AUTOSAR XML (schema 00046)
package /MICROSAR/Csm_swc/DataTypes
  22 x impl type:
    Csm_VerifyResultType: compu {0=CRYPTO_E_VER_OK, 1=CRYPTO_E_VER_NOT_OK}, range raw 0..1, implementation-data-type=uint8  # The data type Csm_VerifyResultType indicates the result of a verification operation.
    Csm_ConfigIdType: range raw 0..65535, implementation-data-type=uint16  # The data type Csm_ConfigIdType identifies a configuration data set, which is unique within a service.
    Crypto_OperationModeType: compu {1=CRYPTO_OPERATIONMODE_START, 2=CRYPTO_OPERATIONMODE_UPDATE, 3=CRYPTO_OPERATIONMODE_STREAMSTART, 4=CRYPTO_OPERATIONMODE_FINISH, 7=CRYPTO_OPERATIONMODE_SINGLECALL}, range raw 0..7, implementation-data-type=uint8  # Enum which operation shall be performed. This enum is constructed from a bit mask, where the first bit indicates “Start”, the second “Update” and the third “Finish”.
    Crypto_VerifyResultType: compu {0=CRYPTO_E_VER_OK, 1=CRYPTO_E_VER_NOT_OK}, range raw 0..1, implementation-data-type=uint8  # Enumeration of the result type of verification operations.
    Csm_KeyElementEnumType:  # Enum which lists the most common Crypto Key Elements IDs
      compu {1=CRYPTO_KE_MAC_KEY, 2=CRYPTO_KE_MAC_PROOF, 1=CRYPTO_KE_SIGNATURE_KEY, 3=CRYPTO_KE_RANDOM_SEED_STATE, 4=CRYPTO_KE_RANDOM_ALGORITHM, 1=CRYPTO_KE_CIPHER_KEY, 5=CRYPTO_KE_CIPHER_IV, 6=CRYPTO_KE_CIPHER_PROOF, 7=CRYPTO_KE_CIPHER_2NDKEY, 8=CRYPTO_KE_KEYEXCHANGE_BASE, 9=CRYPTO_KE_KEYEXCHANGE_PRIVKEY, 10=CRYPTO_KE_KEYEXCHANGE_OWNPUBKEY, 1=CRYPTO_KE_KEYEXCHANGE_SHAREDVALUE, 12=CRYPTO_KE_KEYEXCHANGE_ALGORITHM, 1=CRYPTO_KE_KEYDERIVATION_PASSWORD, 13=CRYPTO_KE_KEYDERIVATION_SALT, 14=CRYPTO_KE_KEYDERIVATION_ITERATIONS, 15=CRYPTO_KE_KEYDERIVATION_ALGORITHM, 1=CRYPTO_KE_KEYGENERATE_KEY, 16=CRYPTO_KE_KEYGENERATE_SEED, 17=CRYPTO_KE_KEYGENERATE_ALGORITHM, 0=CRYPTO_KE_CERTIFICATE_DATA, 18=CRYPTO_KE_CERTIFICATE_PARSING_FORMAT, 19=CRYPTO_KE_CERTIFICATE_CURRENT_TIME, 20=CRYPTO_KE_CERTIFICATE_VERSION, 21=CRYPTO_KE_CERTIFICATE_SERIALNUMBER, 22=CRYPTO_KE_CERTIFICATE_SIGNATURE_ALGORITHM, 23=CRYPTO_KE_CERTIFICATE_ISSUER, 24=CRYPTO_KE_CERTIFICATE_VALIDITY_NOT_BEFORE, 25=CRYPTO_KE_CERTIFICATE_VALIDITY_NOT_AFTER, 26=CRYPTO_KE_CERTIFICATE_SUBJECT, 1=CRYPTO_KE_CERTIFICATE_SUBJECT_PUBLIC_KEY, 27=CRYPTO_KE_CERTIFICATE_EXTENSIONS, 28=CRYPTO_KE_CERTIFICATE_SIGNATURE}
      range raw 0..4294967295
      implementation-data-type=uint32
    Csm_DataPtr: category=DATA_REFERENCE, sw-pointer-target-props={target-category=TYPE_REFERENCE, implementation-data-type=uint8}
    Csm_const_DataPtr: category=DATA_REFERENCE, sw-pointer-target-props={target-category=TYPE_REFERENCE, implementation-data-type=uint8, sw-impl-policy=CONST}
    Csm_LengthPtr: category=DATA_REFERENCE, sw-pointer-target-props={target-category=TYPE_REFERENCE, implementation-data-type=uint32}
    Csm_VerifyResultPtr: category=DATA_REFERENCE, sw-pointer-target-props={target-category=TYPE_REFERENCE, implementation-data-type=Csm_VerifyResultType}
    Csm_ResultType: compu {1=E_NOT_OK, 2=E_SMALL_BUFFER, 3=E_ENTROPY_EXHAUSTION, 4=E_KEY_READ_FAIL, 5=E_KEY_NOT_AVAILABLE, 6=E_KEY_NOT_VALID, 7=E_JOB_CANCELED, 8=E_KEY_EMPTY}, range raw 0..8, implementation-data-type=uint8  # Csm module specific return values for use in Std_ReturnType that could occur during asynchronous job processing.
    Crypto_ResultType: compu {1=E_NOT_OK, 2=CRYPTO_E_BUSY, 4=CRYPTO_E_ENTROPY_EXHAUSTED, 6=CRYPTO_E_KEY_READ_FAIL, 7=CRYPTO_E_KEY_WRITE_FAIL, 8=CRYPTO_E_KEY_NOT_AVAILABLE, 9=CRYPTO_E_KEY_NOT_VALID, 10=CRYPTO_E_KEY_SIZE_MISMATCH, 12=CRYPTO_E_JOB_CANCELED, 13=CRYPTO_E_KEY_EMPTY}, range raw 0..13, implementation-data-type=uint8  # Return for Std_ReturnType for Cryptostack.
    dtRef_: implementation-data-type=uint8
    Csm_DecryptDataType_CsmPrimitives_AES128_Decrypt: category=ARRAY, sw-calibration-access=READ-ONLY  # Used as Buffer for service.
      element Csm_DecryptDataType_CsmPrimitives_AES128_DecryptElement: array-size=16, array-size-semantics=FIXED-SIZE, implementation-data-type=uint8
    Csm_DecryptResultType_CsmPrimitives_AES128_Decrypt: category=ARRAY, sw-calibration-access=READ-ONLY  # Used as Buffer for service.
      element Csm_DecryptResultType_CsmPrimitives_AES128_DecryptElement: array-size=16, array-size-semantics=FIXED-SIZE, implementation-data-type=uint8
    Csm_EncryptDataType_CsmPrimitives_AES128_Encrypt: category=ARRAY, sw-calibration-access=READ-ONLY  # Used as Buffer for service.
      element Csm_EncryptDataType_CsmPrimitives_AES128_EncryptElement: array-size=16, array-size-semantics=FIXED-SIZE, implementation-data-type=uint8
    Csm_EncryptResultType_CsmPrimitives_AES128_Encrypt: category=ARRAY, sw-calibration-access=READ-ONLY  # Used as Buffer for service.
      element Csm_EncryptResultType_CsmPrimitives_AES128_EncryptElement: array-size=16, array-size-semantics=FIXED-SIZE, implementation-data-type=uint8
    Csm_KeyDataType_CsmKey: category=ARRAY, sw-calibration-access=READ-ONLY  # Used as Buffer for service.
      element Csm_KeyDataType_CsmKeyElement: array-size=16, array-size-semantics=FIXED-SIZE, implementation-data-type=uint8
    Csm_PublicValueDataType_CsmKey: category=ARRAY, sw-calibration-access=READ-ONLY  # Used as Buffer for service.
      element Csm_PublicValueDataType_CsmKeyElement: array-size=16, array-size-semantics=FIXED-SIZE, implementation-data-type=uint8
    Csm_SeedDataTypeCsmKey: category=ARRAY, sw-calibration-access=READ-ONLY  # Used as Buffer for service.
      element Csm_SeedDataTypeCsmKeyElement: array-size=16, array-size-semantics=FIXED-SIZE, implementation-data-type=uint8
    Csm_KeyDataType_CsmKey_RandomSeed: category=ARRAY, sw-calibration-access=READ-ONLY  # Used as Buffer for service.
      element Csm_KeyDataType_CsmKey_RandomSeedElement: array-size=16, array-size-semantics=FIXED-SIZE, implementation-data-type=uint8
    Csm_PublicValueDataType_CsmKey_RandomSeed: category=ARRAY, sw-calibration-access=READ-ONLY  # Used as Buffer for service.
      element Csm_PublicValueDataType_CsmKey_RandomSeedElement: array-size=16, array-size-semantics=FIXED-SIZE, implementation-data-type=uint8
    Csm_SeedDataTypeCsmKey_RandomSeed: category=ARRAY, sw-calibration-access=READ-ONLY  # Used as Buffer for service.
      element Csm_SeedDataTypeCsmKey_RandomSeedElement: array-size=16, array-size-semantics=FIXED-SIZE, implementation-data-type=uint8
package /MICROSAR/Csm_swc/Interfaces
  5 x client server interface, all with is-service=true, service-kind=CRYPTO-SERVICE-MANAGER:
    CsmKeyManagement_CsmKey  # Interface to execute the key management functions.
      13 x operation:
        CertificateParse: possible-error=[CsmKeyManagement_CsmKey/E_NOT_OK, CsmKeyManagement_CsmKey/CSM_E_BUSY, CsmKeyManagement_CsmKey/CSM_E_KEY_EMPTY]  # This function shall dispatch the certificate parse function to the CRYIF.
        CertificateVerify: possible-error=[CsmKeyManagement_CsmKey/E_NOT_OK, CsmKeyManagement_CsmKey/CSM_E_BUSY, CsmKeyManagement_CsmKey/CSM_E_KEY_EMPTY]  # Verifies the certificate stored in the key referenced by verifyKeyId with the certificate stored in the key referenced by keyId. Note: Only certificates stored in the same Crypto Driver can be verified against each other. If the key element CRYPTO_KE_CERTIFICATE_CURRENT_TIME is used for the verification of the validity period of the certificate indentified by verifyKeyId, it shall have the same format as the timestamp in the certificate.
          arg verifyKeyId: type=uint32, direction=IN  # Holds the identifier of the key containing the certificate to be verified.
          arg verifyPtr: type=Crypto_VerifyResultType, direction=OUT  # Contains the result of the certificate verification.
        KeyCopy: possible-error=[CsmKeyManagement_CsmKey/E_NOT_OK, CsmKeyManagement_CsmKey/CSM_E_BUSY, CsmKeyManagement_CsmKey/CSM_E_SMALL_BUFFER, CsmKeyManagement_CsmKey/CSM_E_KEY_READ_FAIL, CsmKeyManagement_CsmKey/CSM_E_KEY_WRITE_FAIL, CsmKeyManagement_CsmKey/CSM_E_KEY_SIZE_MISMATCH, CsmKeyManagement_CsmKey/CSM_E_KEY_EMPTY]  # This function shall copy all key elements from the source key to a target key.
          arg targetKeyId: type=uint32, direction=IN  # Holds the identifier of the key whose key element shall be the destination element.
        KeyDerive: possible-error=[CsmKeyManagement_CsmKey/E_NOT_OK, CsmKeyManagement_CsmKey/CSM_E_BUSY, CsmKeyManagement_CsmKey/CSM_E_KEY_READ_FAIL, CsmKeyManagement_CsmKey/CSM_E_KEY_WRITE_FAIL, CsmKeyManagement_CsmKey/CSM_E_KEY_SIZE_MISMATCH, CsmKeyManagement_CsmKey/CSM_E_KEY_EMPTY]  # Derives a new key by using the key elements in the given key. The given key contains the key elements for the password and salt. The derived key is stored in the key element with the id 1 of the key identified by targetCryptoKeyId.
          arg targetKeyId: type=uint32, direction=IN  # Holds the identifier of the key which is used to store the derived key.
        KeyElementCopy: possible-error=[CsmKeyManagement_CsmKey/E_NOT_OK, CsmKeyManagement_CsmKey/CSM_E_BUSY, CsmKeyManagement_CsmKey/CSM_E_SMALL_BUFFER, CsmKeyManagement_CsmKey/CSM_E_KEY_READ_FAIL, CsmKeyManagement_CsmKey/CSM_E_KEY_WRITE_FAIL, CsmKeyManagement_CsmKey/CSM_E_KEY_SIZE_MISMATCH, CsmKeyManagement_CsmKey/CSM_E_KEY_EMPTY]  # This function shall copy a key elements from one key to a target key.
          arg keyElementId: type=uint32, direction=IN  # Holds the identifier of the key element which shall be the source for the copy operation.
          arg targetKeyId: type=uint32, direction=IN  # Holds the identifier of the key whose key element shall be the destination element.
          arg targetKeyElementId: type=uint32, direction=IN  # Holds the identifier of the key element which shall be the destination for the copy operation.
        KeyElementCopyPartial: possible-error=[CsmKeyManagement_CsmKey/E_NOT_OK, CsmKeyManagement_CsmKey/CSM_E_BUSY, CsmKeyManagement_CsmKey/CSM_E_KEY_NOT_AVAILABLE, CsmKeyManagement_CsmKey/CSM_E_KEY_READ_FAIL, CsmKeyManagement_CsmKey/CSM_E_KEY_WRITE_FAIL, CsmKeyManagement_CsmKey/CSM_E_KEY_SIZE_MISMATCH, CsmKeyManagement_CsmKey/CSM_E_KEY_EMPTY]  # This function shall copy parts of a key element from one key to parts of a target key element of a target key.
          6 x arg, all with type=uint32, direction=IN:
            keyElementId  # Holds the identifier of the key element which shall be the source for the copy operation.
            keyElementSourceOffset  # This is the offset of the source key element indicating the start index of the copy operation.
            keyElementTargetOffset  # This is the offset of the destination key element indicating the start index of the copy operation.
            keyElementCopyLength  # Specifies the number of bytes that shall be copied.
            targetKeyId  # Holds the identifier of the key whose key element shall be the destination element.
            targetKeyElementId  # Holds the identifier of the key element which shall be the destination for the copy operation.
        KeyElementGet: possible-error=[CsmKeyManagement_CsmKey/E_NOT_OK, CsmKeyManagement_CsmKey/CSM_E_BUSY, CsmKeyManagement_CsmKey/CSM_E_SMALL_BUFFER, CsmKeyManagement_CsmKey/CSM_E_KEY_READ_FAIL, CsmKeyManagement_CsmKey/CSM_E_KEY_NOT_AVAILABLE, CsmKeyManagement_CsmKey/CSM_E_KEY_EMPTY]  # Retrieves the key element bytes from a specific key element of the key and stores the key element in the provided buffer.
          arg keyElementId: type=uint32, direction=IN  # Holds the identifier of the key element to be read.
          arg keyPtr: type=Csm_KeyDataType_CsmKey, direction=OUT, server-argument-impl-policy=USE-ARRAY-BASE-TYPE  # Holds the data to the key element bytes to be written.
          arg keyLength: type=uint32, direction=INOUT  # Contains the number of key element bytes.
        KeyElementSet: possible-error=[CsmKeyManagement_CsmKey/E_NOT_OK, CsmKeyManagement_CsmKey/CSM_E_BUSY, CsmKeyManagement_CsmKey/CSM_E_KEY_WRITE_FAIL, CsmKeyManagement_CsmKey/CSM_E_KEY_NOT_AVAILABLE, CsmKeyManagement_CsmKey/CSM_E_KEY_SIZE_MISMATCH]  # Sets the given key element bytes to the key.
          arg keyElementId: type=uint32, direction=IN  # Holds the identifier of the key element to be written.
          arg keyPtr: type=Csm_KeyDataType_CsmKey, direction=IN, server-argument-impl-policy=USE-ARRAY-BASE-TYPE  # Holds the data to the key element bytes to be processed.
          arg keyLength: type=uint32, direction=IN  # Contains the number of key element bytes.
        KeyExchangeCalcPubVal: possible-error=[CsmKeyManagement_CsmKey/E_NOT_OK, CsmKeyManagement_CsmKey/CSM_E_BUSY, CsmKeyManagement_CsmKey/CSM_E_SMALL_BUFFER, CsmKeyManagement_CsmKey/CSM_E_KEY_EMPTY]  # Calculates the public value of the current user for the key exchange and stores the public key in the provided buffer.
          arg publicValuePtr: type=Csm_PublicValueDataType_CsmKey, direction=OUT, server-argument-impl-policy=USE-ARRAY-BASE-TYPE  # Holds a pointer to the memory location in which the public value length in bytes is stored. On calling this function, this parameter shall contain the size of the buffer in bytes provided by publicValuePtr. When the request has finished, the actual length of the returned value shall be stored.
          arg publicValueLengthPtr: type=uint32, direction=INOUT  # Contains the pointer to the data where the public value shall be stored.
        KeyExchangeCalcSecret: possible-error=[CsmKeyManagement_CsmKey/E_NOT_OK, CsmKeyManagement_CsmKey/CSM_E_BUSY, CsmKeyManagement_CsmKey/CSM_E_SMALL_BUFFER, CsmKeyManagement_CsmKey/CSM_E_KEY_EMPTY]  # Calculates the shared secret key for the key exchange with the key material of the key identified by the keyId and the partner public key. The shared secret key is stored as a key element in the same key.
          arg partnerPublicValuePtr: type=Csm_PublicValueDataType_CsmKey, direction=IN, server-argument-impl-policy=USE-ARRAY-BASE-TYPE  # Holds the pointer to the memory location containing the partner's public value.
          arg partnerPublicValueLength: type=uint32, direction=IN  # Contains the number of bytes of the partner public value.
        KeyGenerate: possible-error=[CsmKeyManagement_CsmKey/E_NOT_OK, CsmKeyManagement_CsmKey/CSM_E_BUSY, CsmKeyManagement_CsmKey/CSM_E_KEY_EMPTY]  # Generates new key material and store it in the key identified by keyId.
        KeySetValid: possible-error=[CsmKeyManagement_CsmKey/E_NOT_OK, CsmKeyManagement_CsmKey/CSM_E_BUSY]  # Sets the given key element bytes to the key.
        RandomSeed: possible-error=[CsmKeyManagement_CsmKey/E_NOT_OK, CsmKeyManagement_CsmKey/CSM_E_BUSY]  # Feeds a key element with a random seed.
          arg seedPtr: type=Csm_SeedDataTypeCsmKey, direction=IN, server-argument-impl-policy=USE-ARRAY-BASE-TYPE  # Holds the data which shall be used for the random seed initialization.
          arg seedLength: type=uint32, direction=IN  # Contains the length of the seed in bytes.
      8 x error:
        E_NOT_OK: error-code=1  # The service request failed.
        CSM_E_BUSY: error-code=2  # The service request failed because the service is still busy.
        CSM_E_SMALL_BUFFER: error-code=3  # The service request failed because the provided buffer is too small to store the result.
        CSM_E_KEY_READ_FAIL: error-code=6  # The service request failed because read access was denied.
        CSM_E_KEY_WRITE_FAIL: error-code=7  # The service request failed because write access was denied.
        CSM_E_KEY_NOT_AVAILABLE: error-code=8  # The service request failed because the key is not available.
        CSM_E_KEY_SIZE_MISMATCH: error-code=10  # The service request failed because the key element is not partially accessible and the provided key element length is too short or too long for that key element.
        CSM_E_KEY_EMPTY: error-code=13  # The service request failed because of uninitialized source key element.
    CsmKeyManagement_CsmKey_RandomSeed  # Interface to execute the key management functions.
      13 x operation:
        CertificateParse: possible-error=[CsmKeyManagement_CsmKey_RandomSeed/E_NOT_OK, CsmKeyManagement_CsmKey_RandomSeed/CSM_E_BUSY, CsmKeyManagement_CsmKey_RandomSeed/CSM_E_KEY_EMPTY]  # This function shall dispatch the certificate parse function to the CRYIF.
        CertificateVerify: possible-error=[CsmKeyManagement_CsmKey_RandomSeed/E_NOT_OK, CsmKeyManagement_CsmKey_RandomSeed/CSM_E_BUSY, CsmKeyManagement_CsmKey_RandomSeed/CSM_E_KEY_EMPTY]  # Verifies the certificate stored in the key referenced by verifyKeyId with the certificate stored in the key referenced by keyId. Note: Only certificates stored in the same Crypto Driver can be verified against each other. If the key element CRYPTO_KE_CERTIFICATE_CURRENT_TIME is used for the verification of the validity period of the certificate indentified by verifyKeyId, it shall have the same format as the timestamp in the certificate.
          arg verifyKeyId: type=uint32, direction=IN  # Holds the identifier of the key containing the certificate to be verified.
          arg verifyPtr: type=Crypto_VerifyResultType, direction=OUT  # Contains the result of the certificate verification.
        KeyCopy: possible-error=[CsmKeyManagement_CsmKey_RandomSeed/E_NOT_OK, CsmKeyManagement_CsmKey_RandomSeed/CSM_E_BUSY, CsmKeyManagement_CsmKey_RandomSeed/CSM_E_SMALL_BUFFER, CsmKeyManagement_CsmKey_RandomSeed/CSM_E_KEY_READ_FAIL, CsmKeyManagement_CsmKey_RandomSeed/CSM_E_KEY_WRITE_FAIL, CsmKeyManagement_CsmKey_RandomSeed/CSM_E_KEY_SIZE_MISMATCH, CsmKeyManagement_CsmKey_RandomSeed/CSM_E_KEY_EMPTY]  # This function shall copy all key elements from the source key to a target key.
          arg targetKeyId: type=uint32, direction=IN  # Holds the identifier of the key whose key element shall be the destination element.
        KeyDerive: possible-error=[CsmKeyManagement_CsmKey_RandomSeed/E_NOT_OK, CsmKeyManagement_CsmKey_RandomSeed/CSM_E_BUSY, CsmKeyManagement_CsmKey_RandomSeed/CSM_E_KEY_READ_FAIL, CsmKeyManagement_CsmKey_RandomSeed/CSM_E_KEY_WRITE_FAIL, CsmKeyManagement_CsmKey_RandomSeed/CSM_E_KEY_SIZE_MISMATCH, CsmKeyManagement_CsmKey_RandomSeed/CSM_E_KEY_EMPTY]  # Derives a new key by using the key elements in the given key. The given key contains the key elements for the password and salt. The derived key is stored in the key element with the id 1 of the key identified by targetCryptoKeyId.
          arg targetKeyId: type=uint32, direction=IN  # Holds the identifier of the key which is used to store the derived key.
        KeyElementCopy: possible-error=[CsmKeyManagement_CsmKey_RandomSeed/E_NOT_OK, CsmKeyManagement_CsmKey_RandomSeed/CSM_E_BUSY, CsmKeyManagement_CsmKey_RandomSeed/CSM_E_SMALL_BUFFER, CsmKeyManagement_CsmKey_RandomSeed/CSM_E_KEY_READ_FAIL, CsmKeyManagement_CsmKey_RandomSeed/CSM_E_KEY_WRITE_FAIL, CsmKeyManagement_CsmKey_RandomSeed/CSM_E_KEY_SIZE_MISMATCH, CsmKeyManagement_CsmKey_RandomSeed/CSM_E_KEY_EMPTY]  # This function shall copy a key elements from one key to a target key.
          arg keyElementId: type=uint32, direction=IN  # Holds the identifier of the key element which shall be the source for the copy operation.
          arg targetKeyId: type=uint32, direction=IN  # Holds the identifier of the key whose key element shall be the destination element.
          arg targetKeyElementId: type=uint32, direction=IN  # Holds the identifier of the key element which shall be the destination for the copy operation.
        KeyElementCopyPartial: possible-error=[CsmKeyManagement_CsmKey_RandomSeed/E_NOT_OK, CsmKeyManagement_CsmKey_RandomSeed/CSM_E_BUSY, CsmKeyManagement_CsmKey_RandomSeed/CSM_E_KEY_NOT_AVAILABLE, CsmKeyManagement_CsmKey_RandomSeed/CSM_E_KEY_READ_FAIL, CsmKeyManagement_CsmKey_RandomSeed/CSM_E_KEY_WRITE_FAIL, CsmKeyManagement_CsmKey_RandomSeed/CSM_E_KEY_SIZE_MISMATCH, CsmKeyManagement_CsmKey_RandomSeed/CSM_E_KEY_EMPTY]  # This function shall copy parts of a key element from one key to parts of a target key element of a target key.
          6 x arg, all with type=uint32, direction=IN:
            keyElementId  # Holds the identifier of the key element which shall be the source for the copy operation.
            keyElementSourceOffset  # This is the offset of the source key element indicating the start index of the copy operation.
            keyElementTargetOffset  # This is the offset of the destination key element indicating the start index of the copy operation.
            keyElementCopyLength  # Specifies the number of bytes that shall be copied.
            targetKeyId  # Holds the identifier of the key whose key element shall be the destination element.
            targetKeyElementId  # Holds the identifier of the key element which shall be the destination for the copy operation.
        KeyElementGet: possible-error=[CsmKeyManagement_CsmKey_RandomSeed/E_NOT_OK, CsmKeyManagement_CsmKey_RandomSeed/CSM_E_BUSY, CsmKeyManagement_CsmKey_RandomSeed/CSM_E_SMALL_BUFFER, CsmKeyManagement_CsmKey_RandomSeed/CSM_E_KEY_READ_FAIL, CsmKeyManagement_CsmKey_RandomSeed/CSM_E_KEY_NOT_AVAILABLE, CsmKeyManagement_CsmKey_RandomSeed/CSM_E_KEY_EMPTY]  # Retrieves the key element bytes from a specific key element of the key and stores the key element in the provided buffer.
          arg keyElementId: type=uint32, direction=IN  # Holds the identifier of the key element to be read.
          arg keyPtr: type=Csm_KeyDataType_CsmKey_RandomSeed, direction=OUT, server-argument-impl-policy=USE-ARRAY-BASE-TYPE  # Holds the data to the key element bytes to be written.
          arg keyLength: type=uint32, direction=INOUT  # Contains the number of key element bytes.
        KeyElementSet: possible-error=[CsmKeyManagement_CsmKey_RandomSeed/E_NOT_OK, CsmKeyManagement_CsmKey_RandomSeed/CSM_E_BUSY, CsmKeyManagement_CsmKey_RandomSeed/CSM_E_KEY_WRITE_FAIL, CsmKeyManagement_CsmKey_RandomSeed/CSM_E_KEY_NOT_AVAILABLE, CsmKeyManagement_CsmKey_RandomSeed/CSM_E_KEY_SIZE_MISMATCH]  # Sets the given key element bytes to the key.
          arg keyElementId: type=uint32, direction=IN  # Holds the identifier of the key element to be written.
          arg keyPtr: type=Csm_KeyDataType_CsmKey_RandomSeed, direction=IN, server-argument-impl-policy=USE-ARRAY-BASE-TYPE  # Holds the data to the key element bytes to be processed.
          arg keyLength: type=uint32, direction=IN  # Contains the number of key element bytes.
        KeyExchangeCalcPubVal: possible-error=[CsmKeyManagement_CsmKey_RandomSeed/E_NOT_OK, CsmKeyManagement_CsmKey_RandomSeed/CSM_E_BUSY, CsmKeyManagement_CsmKey_RandomSeed/CSM_E_SMALL_BUFFER, CsmKeyManagement_CsmKey_RandomSeed/CSM_E_KEY_EMPTY]  # Calculates the public value of the current user for the key exchange and stores the public key in the provided buffer.
          arg publicValuePtr: type=Csm_PublicValueDataType_CsmKey_RandomSeed, direction=OUT, server-argument-impl-policy=USE-ARRAY-BASE-TYPE  # Holds a pointer to the memory location in which the public value length in bytes is stored. On calling this function, this parameter shall contain the size of the buffer in bytes provided by publicValuePtr. When the request has finished, the actual length of the returned value shall be stored.
          arg publicValueLengthPtr: type=uint32, direction=INOUT  # Contains the pointer to the data where the public value shall be stored.
        KeyExchangeCalcSecret: possible-error=[CsmKeyManagement_CsmKey_RandomSeed/E_NOT_OK, CsmKeyManagement_CsmKey_RandomSeed/CSM_E_BUSY, CsmKeyManagement_CsmKey_RandomSeed/CSM_E_SMALL_BUFFER, CsmKeyManagement_CsmKey_RandomSeed/CSM_E_KEY_EMPTY]  # Calculates the shared secret key for the key exchange with the key material of the key identified by the keyId and the partner public key. The shared secret key is stored as a key element in the same key.
          arg partnerPublicValuePtr: type=Csm_PublicValueDataType_CsmKey_RandomSeed, direction=IN, server-argument-impl-policy=USE-ARRAY-BASE-TYPE  # Holds the pointer to the memory location containing the partner's public value.
          arg partnerPublicValueLength: type=uint32, direction=IN  # Contains the number of bytes of the partner public value.
        KeyGenerate: possible-error=[CsmKeyManagement_CsmKey_RandomSeed/E_NOT_OK, CsmKeyManagement_CsmKey_RandomSeed/CSM_E_BUSY, CsmKeyManagement_CsmKey_RandomSeed/CSM_E_KEY_EMPTY]  # Generates new key material and store it in the key identified by keyId.
        KeySetValid: possible-error=[CsmKeyManagement_CsmKey_RandomSeed/E_NOT_OK, CsmKeyManagement_CsmKey_RandomSeed/CSM_E_BUSY]  # Sets the given key element bytes to the key.
        RandomSeed: possible-error=[CsmKeyManagement_CsmKey_RandomSeed/E_NOT_OK, CsmKeyManagement_CsmKey_RandomSeed/CSM_E_BUSY]  # Feeds a key element with a random seed.
          arg seedPtr: type=Csm_SeedDataTypeCsmKey_RandomSeed, direction=IN, server-argument-impl-policy=USE-ARRAY-BASE-TYPE  # Holds the data which shall be used for the random seed initialization.
          arg seedLength: type=uint32, direction=IN  # Contains the length of the seed in bytes.
      8 x error:
        E_NOT_OK: error-code=1  # The service request failed.
        CSM_E_BUSY: error-code=2  # The service request failed because the service is still busy.
        CSM_E_SMALL_BUFFER: error-code=3  # The service request failed because the provided buffer is too small to store the result.
        CSM_E_KEY_READ_FAIL: error-code=6  # The service request failed because read access was denied.
        CSM_E_KEY_WRITE_FAIL: error-code=7  # The service request failed because write access was denied.
        CSM_E_KEY_NOT_AVAILABLE: error-code=8  # The service request failed because the key is not available.
        CSM_E_KEY_SIZE_MISMATCH: error-code=10  # The service request failed because the key element is not partially accessible and the provided key element length is too short or too long for that key element.
        CSM_E_KEY_EMPTY: error-code=13  # The service request failed because of uninitialized source key element.
    CsmDecrypt_CsmPrimitives_AES128_Decrypt  # This interface is used to perform the decryption.
      operation Decrypt: possible-error=[CsmDecrypt_CsmPrimitives_AES128_Decrypt/E_NOT_OK, CsmDecrypt_CsmPrimitives_AES128_Decrypt/CSM_E_BUSY, CsmDecrypt_CsmPrimitives_AES128_Decrypt/CSM_E_SMALL_BUFFER, CsmDecrypt_CsmPrimitives_AES128_Decrypt/CSM_E_KEY_NOT_VALID, CsmDecrypt_CsmPrimitives_AES128_Decrypt/CSM_E_KEY_SIZE_MISMATCH, CsmDecrypt_CsmPrimitives_AES128_Decrypt/CSM_E_KEY_EMPTY]  # This interface shall be used to start the Decrypt service of the CSM module.
        4 x arg:
          dataBuffer: type=Csm_DecryptDataType_CsmPrimitives_AES128_Decrypt, direction=IN, server-argument-impl-policy=USE-ARRAY-BASE-TYPE  # Holds a pointer to the data for which a plaintext shall be computed.
          dataLength: type=uint32, direction=IN  # Contains the number of bytes for which the plaintext shall be computed.
          resultBuffer: type=Csm_DecryptResultType_CsmPrimitives_AES128_Decrypt, direction=OUT, server-argument-impl-policy=USE-ARRAY-BASE-TYPE  # Holds a pointer to the memory location which will hold the plaintext. The memory location must have at least the given length.
          resultLength: type=uint32, direction=INOUT  # Holds a pointer to the memory location in which the length information is stored. On calling this function this parameter shall contain the size of the provided buffer. When the request has finished, the actual length of the returned plaintext shall be stored.
      operation CancelJob: possible-error=[CsmDecrypt_CsmPrimitives_AES128_Decrypt/E_NOT_OK, CsmDecrypt_CsmPrimitives_AES128_Decrypt/CSM_E_JOB_CANCELED]  # Cancels the Job.
      7 x error:
        E_NOT_OK: error-code=1  # The service request failed.
        CSM_E_BUSY: error-code=2  # The service request failed because the service is still busy.
        CSM_E_SMALL_BUFFER: error-code=3  # The service request failed because the provided buffer is too small to store the result.
        CSM_E_KEY_NOT_VALID: error-code=9  # The service request failed because the key is not valid.
        CSM_E_KEY_SIZE_MISMATCH: error-code=10  # The service request failed because the key element is not partially accessible and the provided key element length is too short or too long for that key element.
        CSM_E_KEY_EMPTY: error-code=13  # The service request failed because of uninitialized source key element.
        CSM_E_JOB_CANCELED: error-code=12  # The job has been marked to be aborted at the next opportunity. It will be further processed until the job finish notification.
    CsmEncrypt_CsmPrimitives_AES128_Encrypt  # This interface is used to perform the encryption.
      operation Encrypt: possible-error=[CsmEncrypt_CsmPrimitives_AES128_Encrypt/E_NOT_OK, CsmEncrypt_CsmPrimitives_AES128_Encrypt/CSM_E_BUSY, CsmEncrypt_CsmPrimitives_AES128_Encrypt/CSM_E_SMALL_BUFFER, CsmEncrypt_CsmPrimitives_AES128_Encrypt/CSM_E_KEY_NOT_VALID, CsmEncrypt_CsmPrimitives_AES128_Encrypt/CSM_E_KEY_SIZE_MISMATCH, CsmEncrypt_CsmPrimitives_AES128_Encrypt/CSM_E_KEY_EMPTY]  # This interface shall be used to start the Encrypt service of the CSM module.
        4 x arg:
          dataBuffer: type=Csm_EncryptDataType_CsmPrimitives_AES128_Encrypt, direction=IN, server-argument-impl-policy=USE-ARRAY-BASE-TYPE  # Holds a pointer to the data for which a ciphertext shall be computed.
          dataLength: type=uint32, direction=IN  # Contains the number of bytes for which the ciphertext shall be computed.
          resultBuffer: type=Csm_EncryptResultType_CsmPrimitives_AES128_Encrypt, direction=OUT, server-argument-impl-policy=USE-ARRAY-BASE-TYPE  # Holds a pointer to the memory location which will hold the ciphertext. The memory location must have at least the given length.
          resultLength: type=uint32, direction=INOUT  # Holds a pointer to the memory location in which the length information is stored. On calling this function this parameter shall contain the size of the provided buffer. When the request has finished, the actual length of the returned ciphertext shall be stored.
      operation CancelJob: possible-error=[CsmEncrypt_CsmPrimitives_AES128_Encrypt/E_NOT_OK, CsmEncrypt_CsmPrimitives_AES128_Encrypt/CSM_E_JOB_CANCELED]  # Cancels the Job.
      7 x error:
        E_NOT_OK: error-code=1  # The service request failed.
        CSM_E_BUSY: error-code=2  # The service request failed because the service is still busy.
        CSM_E_SMALL_BUFFER: error-code=3  # The service request failed because the provided buffer is too small to store the result.
        CSM_E_KEY_NOT_VALID: error-code=9  # The service request failed because the key is not valid.
        CSM_E_KEY_SIZE_MISMATCH: error-code=10  # The service request failed because the key element is not partially accessible and the provided key element length is too short or too long for that key element.
        CSM_E_KEY_EMPTY: error-code=13  # The service request failed because of uninitialized source key element.
        CSM_E_JOB_CANCELED: error-code=12  # The job has been marked to be aborted at the next opportunity. It will be further processed until the job finish notification.
    CallbackNotification  # Interface for the callback notification.
      operation CallbackNotification
        arg result: type=Csm_ResultType, direction=IN
package /MICROSAR/Csm_swc/ComponentTypes
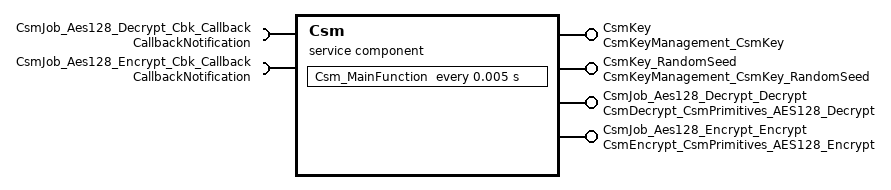
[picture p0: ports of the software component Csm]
  service sw component type Csm: category=SERVICE_COMPONENT
    4 x provide port:
      CsmKey: provided-interface=CsmKeyManagement_CsmKey
      CsmKey_RandomSeed: provided-interface=CsmKeyManagement_CsmKey_RandomSeed
      CsmJob_Aes128_Decrypt_Decrypt: provided-interface=CsmDecrypt_CsmPrimitives_AES128_Decrypt
      CsmJob_Aes128_Encrypt_Encrypt: provided-interface=CsmEncrypt_CsmPrimitives_AES128_Encrypt
    require port CsmJob_Aes128_Decrypt_Cbk_Callback: required-interface=CallbackNotification
    require port CsmJob_Aes128_Encrypt_Cbk_Callback: required-interface=CallbackNotification
    behavior CsmInternalBehavior: handle-termination-and-restart=NO-SUPPORT, included-data-type-set=data-type=[Csm_VerifyResultType, Csm_ConfigIdType, Crypto_OperationModeType, Crypto_VerifyResultType, Csm_KeyElementEnumType, Csm_ResultType, Crypto_ResultType, Csm_KeyDataType_CsmKey, Csm_PublicValueDataType_CsmKey, Csm_SeedDataTypeCsmKey, Csm_KeyDataType_CsmKey_RandomSeed, Csm_PublicValueDataType_CsmKey_RandomSeed, Csm_SeedDataTypeCsmKey_RandomSeed, Csm_DecryptDataType_CsmPrimitives_AES128_Decrypt, Csm_DecryptResultType_CsmPrimitives_AES128_Decrypt, Csm_EncryptDataType_CsmPrimitives_AES128_Encrypt, Csm_EncryptResultType_CsmPrimitives_AES128_Encrypt]
      timing event Timer_Csm_MainFunction: start-on-event=Csm_MainFunction, period=0.005
      30 x operation invoked event:
        OpEventCertificateVerify_CertificateVerify_CsmKey: start-on-event=CertificateVerify, operation=CsmKey.CertificateVerify
        OpEventCertificateVerify_CertificateVerify_CsmKey_RandomSeed: start-on-event=CertificateVerify, operation=CsmKey_RandomSeed.CertificateVerify
        OpEventCertificateParse_CertificateParse_CsmKey_RandomSeed: start-on-event=CertificateParse, operation=CsmKey_RandomSeed.CertificateParse
        OpEventCertificateParse_CertificateParse_CsmKey: start-on-event=CertificateParse, operation=CsmKey.CertificateParse
        OpEventKeyElementCopyPartial_KeyElementCopyPartial_CsmKey: start-on-event=KeyElementCopyPartial, operation=CsmKey.KeyElementCopyPartial
        OpEventKeyElementCopyPartial_KeyElementCopyPartial_CsmKey_RandomSeed: start-on-event=KeyElementCopyPartial, operation=CsmKey_RandomSeed.KeyElementCopyPartial
        OpEventKeyDerive_KeyDerive_CsmKey_RandomSeed: start-on-event=KeyDerive, operation=CsmKey_RandomSeed.KeyDerive
        OpEventKeyDerive_KeyDerive_CsmKey: start-on-event=KeyDerive, operation=CsmKey.KeyDerive
        OpEventRandomSeed_RandomSeed_CsmKey_RandomSeed: start-on-event=RandomSeed, operation=CsmKey_RandomSeed.RandomSeed
        OpEventRandomSeed_RandomSeed_CsmKey: start-on-event=RandomSeed, operation=CsmKey.RandomSeed
        OpEventKeyCopy_KeyCopy_CsmKey: start-on-event=KeyCopy, operation=CsmKey.KeyCopy
        OpEventKeyCopy_KeyCopy_CsmKey_RandomSeed: start-on-event=KeyCopy, operation=CsmKey_RandomSeed.KeyCopy
        OpEventKeyGenerate_KeyGenerate_CsmKey: start-on-event=KeyGenerate, operation=CsmKey.KeyGenerate
        OpEventKeyGenerate_KeyGenerate_CsmKey_RandomSeed: start-on-event=KeyGenerate, operation=CsmKey_RandomSeed.KeyGenerate
        OpEventKeyElementSet_KeyElementSet_CsmKey: start-on-event=KeyElementSet, operation=CsmKey.KeyElementSet
        OpEventKeyElementSet_KeyElementSet_CsmKey_RandomSeed: start-on-event=KeyElementSet, operation=CsmKey_RandomSeed.KeyElementSet
        OpEventKeyElementGet_KeyElementGet_CsmKey_RandomSeed: start-on-event=KeyElementGet, operation=CsmKey_RandomSeed.KeyElementGet
        OpEventKeyElementGet_KeyElementGet_CsmKey: start-on-event=KeyElementGet, operation=CsmKey.KeyElementGet
        OpEventKeyExchangeCalcPubVal_KeyExchangeCalcPubVal_CsmKey_RandomSeed: start-on-event=KeyExchangeCalcPubVal, operation=CsmKey_RandomSeed.KeyExchangeCalcPubVal
        OpEventKeyExchangeCalcPubVal_KeyExchangeCalcPubVal_CsmKey: start-on-event=KeyExchangeCalcPubVal, operation=CsmKey.KeyExchangeCalcPubVal
        OpEventKeyExchangeCalcSecret_KeyExchangeCalcSecret_CsmKey: start-on-event=KeyExchangeCalcSecret, operation=CsmKey.KeyExchangeCalcSecret
        OpEventKeyExchangeCalcSecret_KeyExchangeCalcSecret_CsmKey_RandomSeed: start-on-event=KeyExchangeCalcSecret, operation=CsmKey_RandomSeed.KeyExchangeCalcSecret
        OpEventKeyElementCopy_KeyElementCopy_CsmKey_RandomSeed: start-on-event=KeyElementCopy, operation=CsmKey_RandomSeed.KeyElementCopy
        OpEventKeyElementCopy_KeyElementCopy_CsmKey: start-on-event=KeyElementCopy, operation=CsmKey.KeyElementCopy
        OpEventKeySetValid_KeySetValid_CsmKey: start-on-event=KeySetValid, operation=CsmKey.KeySetValid
        OpEventKeySetValid_KeySetValid_CsmKey_RandomSeed: start-on-event=KeySetValid, operation=CsmKey_RandomSeed.KeySetValid
        OpEventCancelJob_CancelJob_CsmJob_Aes128_Encrypt_Encrypt: start-on-event=CancelJob, operation=CsmJob_Aes128_Encrypt_Encrypt.CancelJob
        OpEventCancelJob_CancelJob_CsmJob_Aes128_Decrypt_Decrypt: start-on-event=CancelJob, operation=CsmJob_Aes128_Decrypt_Decrypt.CancelJob
        OpEventEncrypt_Encrypt_CsmJob_Aes128_Encrypt_Encrypt: start-on-event=Encrypt, operation=CsmJob_Aes128_Encrypt_Encrypt.Encrypt
        OpEventDecrypt_Decrypt_CsmJob_Aes128_Decrypt_Decrypt: start-on-event=Decrypt, operation=CsmJob_Aes128_Decrypt_Decrypt.Decrypt
      port-api-options:
        {enable-take-address=true, indirect-api=false, port-defined-argument-value{value=keyId:0, value-type=uint32}, port=CsmKey}
        {enable-take-address=true, indirect-api=false, port-defined-argument-value{value=keyId:3, value-type=uint32}, port=CsmKey_RandomSeed}
        enable-take-address=true, indirect-api=false, port=CsmJob_Aes128_Decrypt_Cbk_Callback
        enable-take-address=true, indirect-api=false, port=CsmJob_Aes128_Encrypt_Cbk_Callback
        {enable-take-address=true, indirect-api=false, port-arg-values=[{value=0, value-type=uint32}, {value=7, value-type=Crypto_OperationModeType}], port=CsmJob_Aes128_Decrypt_Decrypt}
        {enable-take-address=true, indirect-api=false, port-arg-values=[{value=1, value-type=uint32}, {value=7, value-type=Crypto_OperationModeType}], port=CsmJob_Aes128_Encrypt_Encrypt}
      17 x runnable:
        Csm_MainFunction
          sync call OpServerCallCsm_MainFunction_CallbackNotification_CsmJob_Aes128_Decrypt_Cbk_Callback: operation=CsmJob_Aes128_Decrypt_Cbk_Callback.CallbackNotification, timeout=0
          sync call OpServerCallCsm_MainFunction_CallbackNotification_CsmJob_Aes128_Encrypt_Cbk_Callback: operation=CsmJob_Aes128_Encrypt_Cbk_Callback.CallbackNotification, timeout=0
        CertificateVerify: can-be-invoked-concurrently=true, symbol=Csm_CertificateVerify
        CertificateParse: can-be-invoked-concurrently=true, symbol=Csm_CertificateParse
        KeyElementCopyPartial: can-be-invoked-concurrently=true, symbol=Csm_KeyElementCopyPartial
        KeyDerive: can-be-invoked-concurrently=true, symbol=Csm_KeyDerive
        RandomSeed: can-be-invoked-concurrently=true, symbol=Csm_RandomSeed
        KeyCopy: can-be-invoked-concurrently=true, symbol=Csm_KeyCopy
        KeyGenerate: can-be-invoked-concurrently=true, symbol=Csm_KeyGenerate
        KeyElementSet: can-be-invoked-concurrently=true, symbol=Csm_KeyElementSet
        KeyElementGet: can-be-invoked-concurrently=true, symbol=Csm_KeyElementGet
        KeyExchangeCalcPubVal: can-be-invoked-concurrently=true, symbol=Csm_KeyExchangeCalcPubVal
        KeyExchangeCalcSecret: can-be-invoked-concurrently=true, symbol=Csm_KeyExchangeCalcSecret
        KeyElementCopy: can-be-invoked-concurrently=true, symbol=Csm_KeyElementCopy
        KeySetValid: can-be-invoked-concurrently=true, symbol=Csm_KeySetValid
        CancelJob: can-be-invoked-concurrently=true, symbol=Csm_CancelJob
        Encrypt: can-be-invoked-concurrently=true, symbol=Csm_Encrypt
        Decrypt: can-be-invoked-concurrently=true, symbol=Csm_Decrypt
  swc implementation CsmImplementation: programming-language=C, behavior=CsmInternalBehavior
